# ATmega64HVE2 register map
Vendor: Atmel; File version: 1.0
CPU: other r0p0, little endian, no MPU, no FPU, 4 interrupt priority bits
Registers are 8-bit, read-write, reset 0x0 unless marked. A register's access mark holds for its fields unless they carry their own. Offsets are from the block's base; [hi:lo] are bit positions.

## TC0 — Timer/Counter, 16-bit
Base 0x00800035
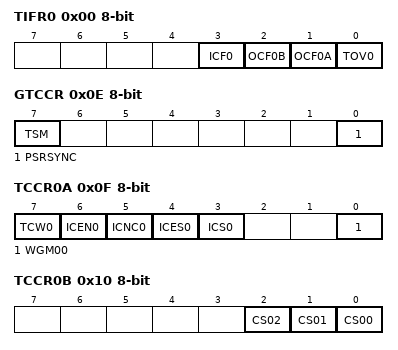
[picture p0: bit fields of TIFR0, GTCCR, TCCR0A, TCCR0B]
0x00 TIFR0 — Timer/Counter Interrupt Flag register (read-only for debugger)
  [3] ICF0 — Timer/Counter 0 Input Capture Flag
  [2] OCF0B — Timer/Counter0 Output Compare Flag B
  [1] OCF0A — Timer/Counter0 Output Compare Flag A
  [0] TOV0 — Timer/Counter0 Overflow Flag
0x0E GTCCR — General Timer/Counter Control Register
  [7] TSM — Timer/Counter Synchronization Mode
  [0] PSRSYNC — Prescaler Reset
0x0F TCCR0A — Timer/Counter 0 Control Register A
  [7] TCW0 — Timer/Counter Width
  [6] ICEN0 — Input Capture Mode Enable
  [5] ICNC0 — Input Capture Noise Canceler
  [4] ICES0 — Input Capture Edge Select
  [3] ICS0 — Input Capture Select
  [0] WGM00 — Waveform Generation Mode
0x10 TCCR0B — Timer/Counter0 Control Register B
  [2] CS02 — Clock Select0 bit 2
  [1] CS01 — Clock Select0 bit 1
  [0] CS00 — Clock Select0 bit 0
    0=NO_CLOCK_SOURCE_STOPPED; 1=RUNNING_NO_PRESCALING
0x11 TCNT0 16-bit (reset mask 0xFF) — Timer Counter 0 Bytes
0x13 OCR0A — Output Compare Register 0A
0x14 OCR0B — Output Compare Register B
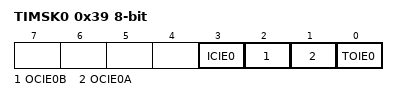
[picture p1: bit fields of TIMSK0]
0x39 TIMSK0 — Timer/Counter Interrupt Mask Register
  [3] ICIE0 — Timer/Counter n Input Capture Interrupt Enable
  [2] OCIE0B — Timer/Counter0 Output Compare B Interrupt Enable
  [1] OCIE0A — Timer/Counter0 Output Compare A Interrupt Enable
  [0] TOIE0 — Timer/Counter0 Overflow Interrupt Enable

## TC1 — Timer/Counter, 16-bit
Base 0x00800036
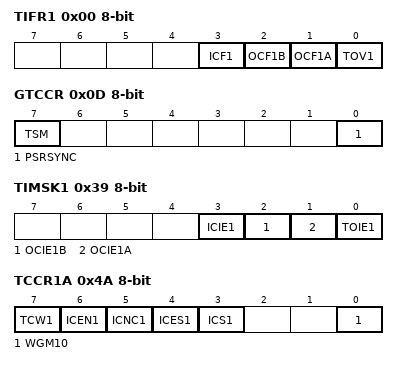
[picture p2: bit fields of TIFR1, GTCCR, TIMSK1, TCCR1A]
0x00 TIFR1 — Timer/Counter Interrupt Flag register (read-only for debugger)
  [3] ICF1 — Timer/Counter 1 Input Capture Flag
  [2] OCF1B — Timer/Counter1 Output Compare Flag B
  [1] OCF1A — Timer/Counter1 Output Compare Flag A
  [0] TOV1 — Timer/Counter1 Overflow Flag
0x0D GTCCR — General Timer/Counter Control Register
  [7] TSM — Timer/Counter Synchronization Mode
  [0] PSRSYNC — Prescaler Reset
0x39 TIMSK1 — Timer/Counter Interrupt Mask Register
  [3] ICIE1 — Timer/Counter n Input Capture Interrupt Enable
  [2] OCIE1B — Timer/Counter1 Output Compare B Interrupt Enable
  [1] OCIE1A — Timer/Counter1 Output Compare A Interrupt Enable
  [0] TOIE1 — Timer/Counter1 Overflow Interrupt Enable
0x4A TCCR1A — Timer/Counter 1 Control Register A
  [7] TCW1 — Timer/Counter Width
  [6] ICEN1 — Input Capture Mode Enable
  [5] ICNC1 — Input Capture Noise Canceler
  [4] ICES1 — Input Capture Edge Select
  [3] ICS1 — Input Capture Select
  [0] WGM10 — Waveform Generation Mode
0x4B TCCR1B — Timer/Counter1 Control Register B
  [2:0] CS — Clock Select1 bis
    0=NO_CLOCK_SOURCE_STOPPED; 1=RUNNING_NO_PRESCALING; 2=RUNNING_CLK_8; 3=RUNNING_CLK_64; 4=RUNNING_CLK_256; 5=RUNNING_CLK_1024; 6=RUNNING_EXTCLK_TN_FALLING_EDGE; 7=RUNNING_EXTCLK_TN_RISING_EDGE
0x4E TCNT1 16-bit (reset mask 0xFF) — Timer Counter 1 Bytes
0x52 OCR1A — Output Compare Register 1A
0x53 OCR1B — Output Compare Register B

## WAKEUP_TIMER
Base 0x00800062
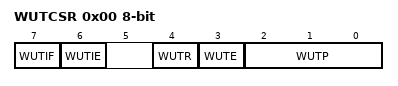
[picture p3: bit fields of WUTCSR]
0x00 WUTCSR — Wake-up Timer Control and Status Register (read-only for debugger)
  [7] WUTIF — Wake-up Timer Interrupt Flag
  [6] WUTIE — Wake-up Timer Interrupt Enable
  [4] WUTR — Wake-up Timer Reset
  [3] WUTE — Wake-up Timer Enable
  [2:0] WUTP — Wake-up Timer Prescaler Bits

## WDT — Watchdog Timer
Base 0x00800060
0x00 WDTCSR — Watchdog Timer Control Register (read-only for debugger)
  [7] WDIF — Watchdog Timeout Interrupt Flag
  [6] WDIE — Watchdog Timeout Interrupt Enable
  [4] WDCE — Watchdog Change Enable
  [3] WDE — Watch Dog Enable
  [5:0] WDP — Watchdog Timer Prescaler Bits
    0=OSCILLATOR_CYCLES_2K; 1=OSCILLATOR_CYCLES_4K; 2=OSCILLATOR_CYCLES_8K; 3=OSCILLATOR_CYCLES_16K; 4=OSCILLATOR_CYCLES_32K; 5=OSCILLATOR_CYCLES_64K; 6=OSCILLATOR_CYCLES_128K; 7=OSCILLATOR_CYCLES_256K
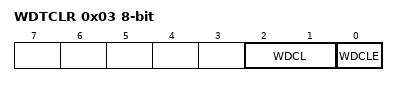
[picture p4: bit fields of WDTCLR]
0x03 WDTCLR — Watchdog Timer Configuration Lock Register
  [2:1] WDCL — Watchdog Timer Configuration Lock bits
  [0] WDCLE — Watchdog Timer Configuration Lock Enable
